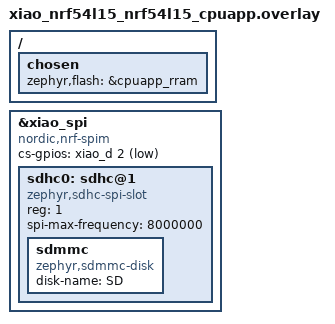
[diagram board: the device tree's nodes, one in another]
/*
 * Copyright (c) 2025 Seeed Technology Co.,Ltd
 *
 * SPDX-License-Identifier: Apache-2.0
 */

/*
 * SD Card configuration for XIAO nRF54L15 Expansion Board
 * 
 * The SD card is connected via SPI on the XIAO expansion board:
 * - MOSI: D10 (xiao_spi)
 * - MISO: D9  (xiao_spi)
 * - SCK:  D8  (xiao_spi)
 * - CS:   D2  (GPIO)
 */

&xiao_spi {
	compatible = "nordic,nrf-spim";
	status = "okay";
	cs-gpios = <&xiao_d 2 GPIO_ACTIVE_LOW>;

	sdhc0: sdhc@1 {
		compatible = "zephyr,sdhc-spi-slot";
		reg = <1>;
		status = "okay";
		
		sdmmc {
			compatible = "zephyr,sdmmc-disk";
			disk-name = "SD";
			status = "okay";
		};

		/* SD card SPI frequency - 8MHz is safe for most cards */
		spi-max-frequency = <8000000>;
	};
};

/ {
	chosen {
		zephyr,flash = &cpuapp_rram;
	};
};
